AUTOSAR XML (schema 4-2-2)
standard types defined: uint8
package /Acme/Chassis/Types
  impl type uint8_impl: category=VALUE, base-type=uint8
  base type int16: category=FIXED_LENGTH, base-type-size=16, base-type-encoding=2C, native-declaration=int16_t
  impl type int16_impl: category=VALUE, base-type=int16
package /Acme/Chassis/Interfaces
  client server interface IBrakeControlService  # Brake control diagnostic service (anonymized fixture).
    operation SetBrakeMode
      arg requestedMode: type=uint8_impl, direction=IN, server-argument-impl-policy=USE-ARGUMENT-TYPE
      arg acceptedMode: type=uint8_impl, direction=OUT, server-argument-impl-policy=USE-ARGUMENT-TYPE
    operation AdjustBrakeBias
      arg biasAdjustment: type=int16_impl, direction=INOUT, server-argument-impl-policy=USE-ARGUMENT-TYPE
package /Acme/Chassis/Components
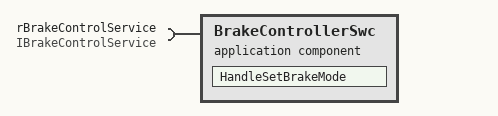
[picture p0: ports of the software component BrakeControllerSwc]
  application sw component type BrakeControllerSwc  # Brake controller application component (anonymized fixture).
    require port rBrakeControlService: required-interface=IBrakeControlService
    behavior BrakeControllerSwc_InternalBehavior
      operation invoked event OIE_SetBrakeMode: start-on-event=HandleSetBrakeMode, operation=rBrakeControlService.SetBrakeMode
      runnable HandleSetBrakeMode
